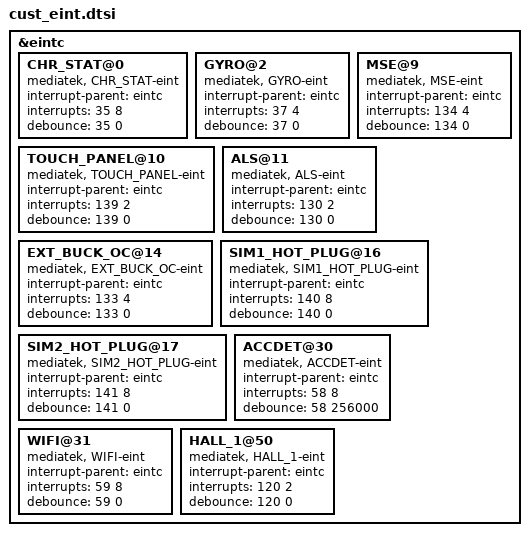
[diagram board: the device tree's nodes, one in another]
/*
 * Generated by MTK SP DrvGen Version 03.13.6 for MT6752. Copyright MediaTek Inc. (C) 2013.
 * Wed Dec 30 20:07:53 2015
 * Do Not Modify the File.
 */

/*************************
 * EINT DTSI File
*************************/

&eintc {
	CHR_STAT@0 {
		compatible = "mediatek, CHR_STAT-eint";
		interrupt-parent = <&eintc>;
		interrupts = <35 8>;
		debounce = <35 0>;
	};

	GYRO@2 {
		compatible = "mediatek, GYRO-eint";
		interrupt-parent = <&eintc>;
		interrupts = <37 4>;
		debounce = <37 0>;
	};

	MSE@9 {
		compatible = "mediatek, MSE-eint";
		interrupt-parent = <&eintc>;
		interrupts = <134 4>;
		debounce = <134 0>;
	};

	TOUCH_PANEL@10 {
		compatible = "mediatek, TOUCH_PANEL-eint";
		interrupt-parent = <&eintc>;
		interrupts = <139 2>;
		debounce = <139 0>;
	};

	ALS@11 {
		compatible = "mediatek, ALS-eint";
		interrupt-parent = <&eintc>;
		interrupts = <130 2>;
		debounce = <130 0>;
	};

	EXT_BUCK_OC@14 {
		compatible = "mediatek, EXT_BUCK_OC-eint";
		interrupt-parent = <&eintc>;
		interrupts = <133 4>;
		debounce = <133 0>;
	};

	SIM1_HOT_PLUG@16 {
		compatible = "mediatek, SIM1_HOT_PLUG-eint";
		interrupt-parent = <&eintc>;
		interrupts = <140 8>;
		debounce = <140 0>;
	};

	SIM2_HOT_PLUG@17 {
		compatible = "mediatek, SIM2_HOT_PLUG-eint";
		interrupt-parent = <&eintc>;
		interrupts = <141 8>;
		debounce = <141 0>;
	};

	ACCDET@30 {
		compatible = "mediatek, ACCDET-eint";
		interrupt-parent = <&eintc>;
		interrupts = <58 8>;
		debounce = <58 256000>;
	};

	WIFI@31 {
		compatible = "mediatek, WIFI-eint";
		interrupt-parent = <&eintc>;
		interrupts = <59 8>;
		debounce = <59 0>;
	};

	HALL_1@50 {
		compatible = "mediatek, HALL_1-eint";
		interrupt-parent = <&eintc>;
		interrupts = <120 2>;
		debounce = <120 0>;
	};

};
